VERSION ""

NS_ :

BS_:

BU_: OBD SBCM

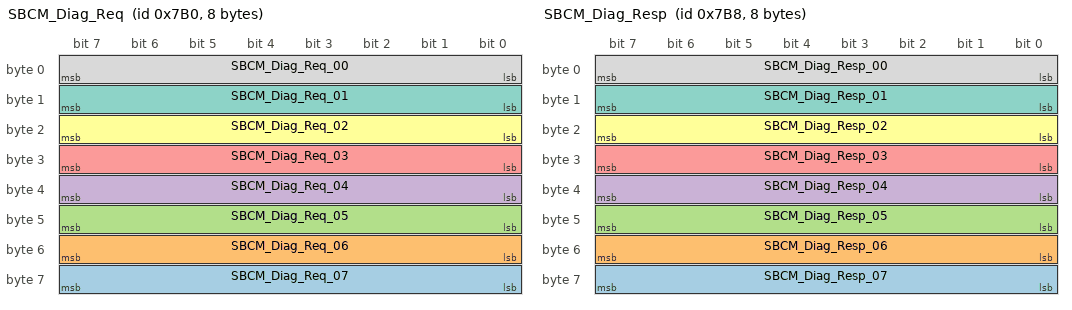
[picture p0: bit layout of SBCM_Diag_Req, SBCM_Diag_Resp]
BO_ 1968 SBCM_Diag_Req: 8 OBD
 SG_ SBCM_Diag_Req_07 : 56|8@1- (1,0) [-128|127] ""  SBCM
 SG_ SBCM_Diag_Req_06 : 48|8@1- (1,0) [-128|127] ""  SBCM
 SG_ SBCM_Diag_Req_05 : 40|8@1- (1,0) [-128|127] ""  SBCM
 SG_ SBCM_Diag_Req_04 : 32|8@1- (1,0) [-128|127] ""  SBCM
 SG_ SBCM_Diag_Req_03 : 24|8@1- (1,0) [-128|127] ""  SBCM
 SG_ SBCM_Diag_Req_02 : 16|8@1- (1,0) [-128|127] ""  SBCM
 SG_ SBCM_Diag_Req_01 : 8|8@1- (1,0) [-128|127] ""  SBCM
 SG_ SBCM_Diag_Req_00 : 0|8@1- (1,0) [-128|127] ""  SBCM

BO_ 1976 SBCM_Diag_Resp: 8 SBCM
 SG_ SBCM_Diag_Resp_07 : 56|8@1- (1,0) [0|0] ""  OBD
 SG_ SBCM_Diag_Resp_06 : 48|8@1- (1,0) [0|0] ""  OBD
 SG_ SBCM_Diag_Resp_05 : 40|8@1- (1,0) [0|0] ""  OBD
 SG_ SBCM_Diag_Resp_04 : 32|8@1- (1,0) [0|0] ""  OBD
 SG_ SBCM_Diag_Resp_03 : 24|8@1- (1,0) [0|0] ""  OBD
 SG_ SBCM_Diag_Resp_02 : 16|8@1- (1,0) [0|0] ""  OBD
 SG_ SBCM_Diag_Resp_01 : 8|8@1- (1,0) [0|0] ""  OBD
 SG_ SBCM_Diag_Resp_00 : 0|8@1- (1,0) [0|0] ""  OBD

BA_DEF_ BO_  "CANFD_BRS" ENUM  "0","1";
BA_DEF_  "DBName" STRING ;
BA_DEF_  "BusType" STRING ;
BA_DEF_ BO_  "VFrameFormat" ENUM  "StandardCAN","ExtendedCAN","reserved","reserved","reserved","reserved","reserved","reserved","reserved","reserved","reserved","reserved","reserved","reserved","StandardCAN_FD","ExtendedCAN_FD";
BA_DEF_DEF_  "CANFD_BRS" "1";
BA_DEF_DEF_  "DBName" "";
BA_DEF_DEF_  "BusType" "";
BA_DEF_DEF_  "VFrameFormat" "StandardCAN";
BA_ "BusType" "CAN FD";
BA_ "DBName" "CAN_FD";
